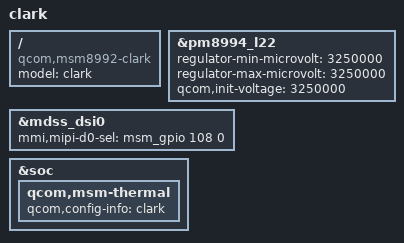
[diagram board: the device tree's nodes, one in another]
/* Copyright (c) 2015, Motorla Mobility LLC. All rights reserved.
 *
 * This program is free software; you can redistribute it and/or modify
 * it under the terms of the GNU General Public License version 2 and
 * only version 2 as published by the Free Software Foundation.
 *
 * This program is distributed in the hope that it will be useful,
 * but WITHOUT ANY WARRANTY; without even the implied warranty of
 * MERCHANTABILITY or FITNESS FOR A PARTICULAR PURPOSE.  See the
 * GNU General Public License for more details.
 */

#include "msm8992-moto-common.dtsi"

/ {
	model = "clark";
	compatible = "qcom,msm8992-clark", "qcom,msm8992-moto", "qcom,msm8994";
};

&pm8994_l22 {
	regulator-min-microvolt = <3250000>;
	regulator-max-microvolt = <3250000>;
	qcom,init-voltage = <3250000>;
};

&mdss_dsi0 {
	mmi,mipi-d0-sel = <&msm_gpio 108 0>;
};

&soc {
	qcom,msm-thermal {
		qcom,config-info = "clark";
	};
};
